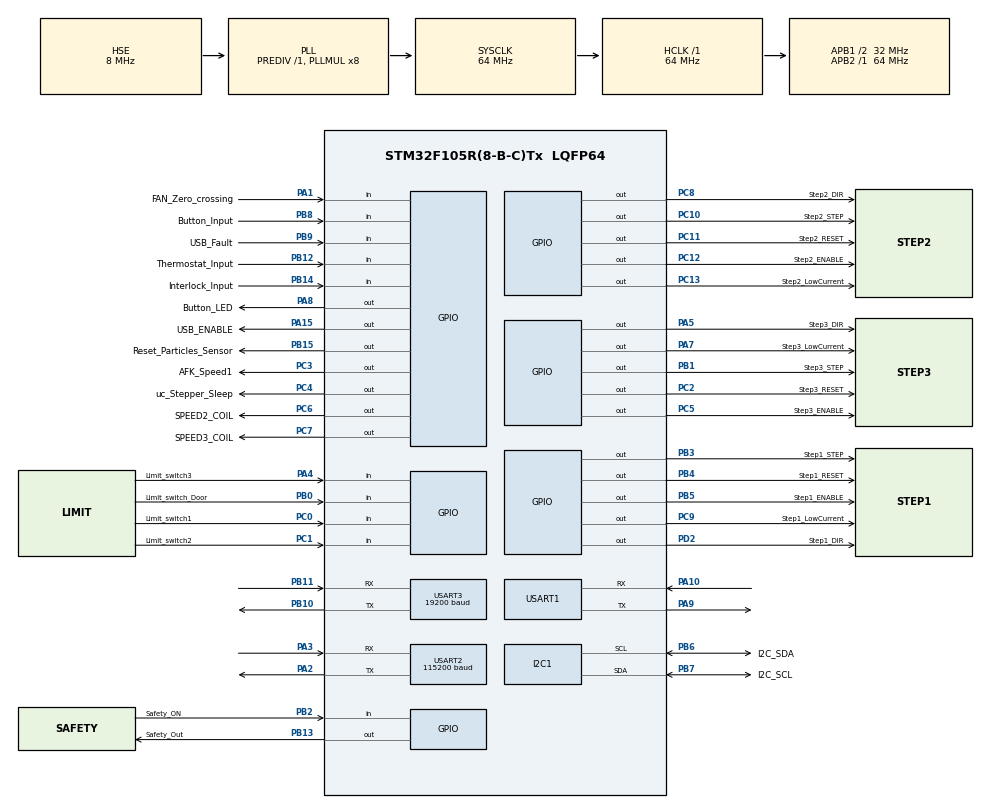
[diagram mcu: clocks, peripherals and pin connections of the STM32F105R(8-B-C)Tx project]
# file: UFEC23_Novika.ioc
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NVIC.I2C1_EV_IRQn=true\:5\:0\:false\:false\:true\:true\:true\:true
PB10.Mode=Asynchronous
RCC.Prediv2=RCC_HSE_PREDIV2_DIV2
PA10.GPIO_PuPd=GPIO_NOPULL
PC12.Signal=GPIO_Output
PB14.GPIO_Label=Interlock_Input
PA3.GPIO_PuPd=GPIO_NOPULL
PC6.GPIO_Label=SPEED2_COIL
VP_RTC_VS_RTC_Activate.Mode=RTC_Enabled
PB6.GPIO_Label=I2C_SDA
PB13.Signal=GPIO_Output
PA5.PinState=GPIO_PIN_SET
PB3.GPIO_Speed=GPIO_SPEED_FREQ_HIGH
RCC.SYSCLKSource=RCC_SYSCLKSOURCE_PLLCLK
USART3.BaudRate=19200
RCC.APB2TimFreq_Value=64000000
PB6.Signal=I2C1_SCL
PC7.Signal=GPIO_Output
PB6.Mode=I2C
PC3.Signal=GPIO_Output
PB2.Signal=GPIO_Input
RCC.PLL2Mul=RCC_PLL2_MUL12
PB12.GPIO_Label=Thermostat_Input
PC4.GPIO_Label=uc_Stepper_Sleep
PB1.GPIO_Speed=GPIO_SPEED_FREQ_HIGH
PB1.GPIO_Label=Step3_STEP
PA8.Signal=GPIO_Output
VP_FREERTOS_VS_CMSIS_V1.Mode=CMSIS_V1
NVIC.I2C1_ER_IRQn=true\:5\:0\:false\:false\:true\:true\:true\:true
Mcu.Package=LQFP64
PB9.Signal=GPIO_Input
PB1.Signal=GPIO_Output
FREERTOS.configUSE_NEWLIB_REENTRANT=0
NVIC.TimeBase=TIM1_UP_IRQn
NVIC.TimeBaseIP=TIM1
PA10.Signal=USART1_RX
VP_RTC_VS_RTC_Calendar.Mode=RTC_Calendar
RCC.APB1TimFreq_Value=64000000
NVIC.USART1_IRQn=true\:5\:0\:false\:false\:true\:true\:true\:true
PA4.GPIO_Label=Limit_switch3
FREERTOS.Tasks01=Algo_task,0,512,Algo_Init,As weak,NULL,Dynamic,NULL,NULL;MotorManager,0,128,Motor_task,As external,NULL,Dynamic,NULL,NULL
PB8.GPIO_PuPd=GPIO_NOPULL
PC2.Signal=GPIO_Output
PC6.Signal=GPIO_Output
PC0.Signal=GPIO_Input
RCC.APB1CLKDivider=RCC_HCLK_DIV2
USART2.BaudRate=115200
PA3.Mode=Asynchronous
PB8.GPIO_Label=Button_Input
PA8.GPIO_Label=Button_LED
PB11.Mode=Asynchronous
PC12.PinState=GPIO_PIN_SET
Dma.USART1_RX.0.Direction=DMA_PERIPH_TO_MEMORY
PA9.Signal=USART1_TX
Dma.USART1_RX.0.PeriphInc=DMA_PINC_DISABLE
PB10.Signal=USART3_TX
PB14.Signal=GPIO_Input
PA5.Signal=GPIO_Output
PC13-TAMPER-RTC.GPIO_Label=Step2_LowCurrent
PB4.GPIO_Label=Step1_RESET
PB15.GPIO_Label=Reset_Particles_Sensor
PA1.GPIO_Label=FAN_Zero_crossing
PA13.Mode=Serial_Wire
PC7.GPIO_Label=SPEED3_COIL
PA4.Signal=GPIO_Input
PB5.Signal=GPIO_Output
PA5.GPIO_Label=Step3_DIR
PC12.GPIO_Label=Step2_ENABLE
USART1.VirtualMode=VM_ASYNC
ProjectManager.HeapSize=0x200
FREERTOS.Timers01=Timer,TimerCallback,osTimerPeriodic,Default,NULL,Dynamic,NULL
NVIC.PriorityGroup=NVIC_PRIORITYGROUP_4
PC3.GPIO_Label=AFK_Speed1
PC3.GPIO_ModeDefaultOutputPP=GPIO_MODE_OUTPUT_PP
PD2.Signal=GPIO_Output
PB0.Signal=GPIO_Input
PC1.Signal=GPIO_Input
PD2.GPIO_Label=Step1_DIR
Mcu.Family=STM32F1
NVIC.USART3_IRQn=true\:5\:0\:false\:false\:true\:true\:true\:true
NVIC.DMA1_Channel5_IRQn=true\:5\:0\:false\:false\:true\:true\:false\:true
PC10.Signal=GPIO_Output
PC0.GPIO_Label=Limit_switch1
PB0.GPIO_Label=Limit_switch_Door
PC10.GPIO_Speed=GPIO_SPEED_FREQ_HIGH
NVIC.TIM1_UP_IRQn=true\:0\:0\:false\:false\:true\:false\:false\:true
PB11.GPIO_PuPd=GPIO_NOPULL
PB13.GPIO_Label=Safety_Out
PB11.Signal=USART3_RX
PB15.Signal=GPIO_Output
PB15.PinState=GPIO_PIN_SET
ProjectManager.StackSize=0x400
PC3.PinState=GPIO_PIN_SET
PD1-OSC_OUT.Signal=RCC_OSC_OUT
VP_RTC_No_RTC_Output.Mode=RTC_OUT_NO
PA15.GPIO_Label=USB_ENABLE
RCC.HCLKFreq_Value=64000000
PB5.PinState=GPIO_PIN_SET
RCC.AHBFreq_Value=64000000
Dma.USART1_RX.0.Priority=DMA_PRIORITY_LOW
FREERTOS.configUSE_TIMERS=1
RCC.PLLMUL=RCC_PLL_MUL8
PA14.Mode=Serial_Wire
VP_SYS_VS_tim1.Mode=TIM1
PC11.GPIO_Label=Step2_RESET
PB7.Signal=I2C1_SDA
SH.S_TIM3_CH1.0=TIM3_CH1
Dma.USART1_RX.0.MemInc=DMA_MINC_ENABLE
FREERTOS.configTOTAL_HEAP_SIZE=8192
PB7.GPIO_Label=I2C_SCL
PA6.Signal=S_TIM3_CH1
USART2.VirtualMode=VM_ASYNC
PA15.Signal=GPIO_Output
PB5.GPIO_Label=Step1_ENABLE
Dma.USART1_RX.0.Mode=DMA_CIRCULAR
PC5.Signal=GPIO_Output
Dma.Request0=USART1_RX
PB4.PinState=GPIO_PIN_SET
PC2.GPIO_Label=Step3_RESET
Dma.USART1_RX.0.Instance=DMA1_Channel5
PA8.PinState=GPIO_PIN_SET
PB4.Signal=GPIO_Output
PA3.Signal=USART2_RX
PB3.GPIO_Label=Step1_STEP
RCC.PLLSourceVirtual=RCC_PLLSOURCE_HSE
PD1-OSC_OUT.Mode=HSE-External-Oscillator
Dma.USART1_RX.0.PeriphDataAlignment=DMA_PDATAALIGN_BYTE
PB9.GPIO_Label=USB_Fault
PC10.GPIO_Label=Step2_STEP
PA10.Mode=Asynchronous
PC9.GPIO_Label=Step1_LowCurrent
PC11.Signal=GPIO_Output
PC8.Signal=GPIO_Output
PC4.Signal=GPIO_Output
PC13-TAMPER-RTC.Signal=GPIO_Output
PD0-OSC_IN.Signal=RCC_OSC_IN
NVIC.USART2_IRQn=true\:5\:0\:false\:false\:true\:true\:true\:true
FREERTOS.INCLUDE_uxTaskGetStackHighWaterMark=1
PC8.GPIO_Label=Step2_DIR
PA13.Signal=SYS_JTMS-SWDIO
PA9.Mode=Asynchronous
ProjectManager.TargetToolchain=STM32CubeIDE
RCC.USBFreq_Value=42666666.666666664
PA1.Signal=GPIO_Input
PD0-OSC_IN.Mode=HSE-External-Oscillator
board=custom
RCC.APB2Freq_Value=64000000
PC11.PinState=GPIO_PIN_SET
PC1.GPIO_Label=Limit_switch2
Dma.USART1_RX.0.MemDataAlignment=DMA_MDATAALIGN_BYTE
Mcu.Name=STM32F105R(8-B-C)Tx
PA2.Signal=USART2_TX
PB3.Signal=GPIO_Output
RCC.SYSCLKFreq_VALUE=64000000
PA7.GPIO_Label=Step3_LowCurrent
PC2.PinState=GPIO_PIN_SET
PC5.PinState=GPIO_PIN_SET
PC5.GPIO_Label=Step3_ENABLE
USART3.VirtualMode=VM_ASYNC
PB7.Mode=I2C
PA14.Signal=SYS_JTCK-SWCLK
PB2.GPIO_Label=Safety_ON
PA2.Mode=Asynchronous
PB8.Signal=GPIO_Input
PC9.Signal=GPIO_Output
RCC.APB1Freq_Value=32000000
PB12.Signal=GPIO_Input
PA7.Signal=GPIO_Output

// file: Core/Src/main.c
/* USER CODE BEGIN Header */
/**
  ******************************************************************************
  * @file           : main.c
  * @brief          : Main program body
  ******************************************************************************
  * @attention
  *
  * <h2><center>&copy; Copyright (c) 2023 STMicroelectronics.
  * All rights reserved.</center></h2>
  *
  * This software component is licensed by ST under Ultimate Liberty license
  * SLA0044, the "License"; You may not use this file except in compliance with
  * the License. You may obtain a copy of the License at:
  *                             www.st.com/SLA0044
  *
  ******************************************************************************
  */
/* USER CODE END Header */
#include "main.h"
#include "cmsis_os.h"

/* USER CODE BEGIN Includes */
#include "Algo.h"
#include "message_buffer.h"
/* USER CODE END Includes */

I2C_HandleTypeDef hi2c1;

RTC_HandleTypeDef hrtc;

UART_HandleTypeDef huart1;
UART_HandleTypeDef huart2;
UART_HandleTypeDef huart3;
DMA_HandleTypeDef hdma_usart1_rx;

osThreadId Algo_taskHandle;
osThreadId MotorManagerHandle;
osTimerId TimerHandle;
/* USER CODE BEGIN PV */
MessageBufferHandle_t MotorControlsHandle;
QueueHandle_t MotorInPlaceHandle;
/* USER CODE END PV */

void SystemClock_Config(void);
static void MX_GPIO_Init(void);
static void MX_DMA_Init(void);
static void MX_RTC_Init(void);
static void MX_USART1_UART_Init(void);
void Algo_Init(void const * argument);
extern void Motor_task(void const * argument);
void TimerCallback(void const * argument);

int main(void)
{

  /* MCU Configuration--------------------------------------------------------*/

  /* Reset of all peripherals, Initializes the Flash interface and the Systick. */
  HAL_Init();

  /* Configure the system clock */
  SystemClock_Config();

  /* Initialize all configured peripherals */
  MX_GPIO_Init();
  MX_DMA_Init();
  MX_I2C1_Init();
  MX_RTC_Init();
  MX_USART1_UART_Init();
  MX_USART3_UART_Init();
  MX_USART2_UART_Init();

  /* Create the timer(s) */
  /* definition and creation of Timer */
  osTimerDef(Timer, TimerCallback);
  TimerHandle = osTimerCreate(osTimer(Timer), osTimerPeriodic, NULL);

  /* USER CODE BEGIN RTOS_QUEUES */
  /* add queues, ... */
	MotorControlsHandle = xMessageBufferCreate(10);
	MotorInPlaceHandle = xQueueCreate(1, sizeof(bool));

  /* USER CODE END RTOS_QUEUES */

  /* Create the thread(s) */
  /* definition and creation of Algo_task */
  osThreadDef(Algo_task, Algo_Init, osPriorityNormal, 0, 512);
  Algo_taskHandle = osThreadCreate(osThread(Algo_task), NULL);

  /* definition and creation of MotorManager */
  osThreadDef(MotorManager, Motor_task, osPriorityAboveNormal, 0, 128);
  MotorManagerHandle = osThreadCreate(osThread(MotorManager), NULL);

  /* Start scheduler */
  osKernelStart();

  /* We should never get here as control is now taken by the scheduler */
  /* Infinite loop */
  while (1)
  {

  }
}

void SystemClock_Config(void)
{
  RCC_OscInitTypeDef RCC_OscInitStruct = {0};
  RCC_ClkInitTypeDef RCC_ClkInitStruct = {0};
  RCC_PeriphCLKInitTypeDef PeriphClkInit = {0};

  /** Initializes the RCC Oscillators according to the specified parameters
  * in the RCC_OscInitTypeDef structure.
  */
  RCC_OscInitStruct.OscillatorType = RCC_OSCILLATORTYPE_LSI|RCC_OSCILLATORTYPE_HSE;
  RCC_OscInitStruct.HSEState = RCC_HSE_ON;
  RCC_OscInitStruct.HSEPredivValue = RCC_HSE_PREDIV_DIV1;
  RCC_OscInitStruct.HSIState = RCC_HSI_ON;
  RCC_OscInitStruct.LSIState = RCC_LSI_ON;
  RCC_OscInitStruct.Prediv1Source = RCC_PREDIV1_SOURCE_HSE;
  RCC_OscInitStruct.PLL.PLLState = RCC_PLL_ON;
  RCC_OscInitStruct.PLL.PLLSource = RCC_PLLSOURCE_HSE;
  RCC_OscInitStruct.PLL.PLLMUL = RCC_PLL_MUL8;
  RCC_OscInitStruct.PLL2.PLL2State = RCC_PLL_NONE;
  if (HAL_RCC_OscConfig(&RCC_OscInitStruct) != HAL_OK)
  {
    Error_Handler();
  }
  /** Initializes the CPU, AHB and APB buses clocks
  */
  RCC_ClkInitStruct.ClockType = RCC_CLOCKTYPE_HCLK|RCC_CLOCKTYPE_SYSCLK
                              |RCC_CLOCKTYPE_PCLK1|RCC_CLOCKTYPE_PCLK2;
  RCC_ClkInitStruct.SYSCLKSource = RCC_SYSCLKSOURCE_PLLCLK;
  RCC_ClkInitStruct.AHBCLKDivider = RCC_SYSCLK_DIV1;
  RCC_ClkInitStruct.APB1CLKDivider = RCC_HCLK_DIV2;
  RCC_ClkInitStruct.APB2CLKDivider = RCC_HCLK_DIV1;

  if (HAL_RCC_ClockConfig(&RCC_ClkInitStruct, FLASH_LATENCY_2) != HAL_OK)
  {
    Error_Handler();
  }
  PeriphClkInit.PeriphClockSelection = RCC_PERIPHCLK_RTC;
  PeriphClkInit.RTCClockSelection = RCC_RTCCLKSOURCE_LSI;
  if (HAL_RCCEx_PeriphCLKConfig(&PeriphClkInit) != HAL_OK)
  {
    Error_Handler();
  }
  /** Configure the Systick interrupt time
  */
  __HAL_RCC_PLLI2S_ENABLE();
}

void MX_I2C1_Init(void)
{

  hi2c1.Instance = I2C1;
  hi2c1.Init.ClockSpeed = 100000;
  hi2c1.Init.DutyCycle = I2C_DUTYCYCLE_2;
  hi2c1.Init.OwnAddress1 = 0;
  hi2c1.Init.AddressingMode = I2C_ADDRESSINGMODE_7BIT;
  hi2c1.Init.DualAddressMode = I2C_DUALADDRESS_DISABLE;
  hi2c1.Init.OwnAddress2 = 0;
  hi2c1.Init.GeneralCallMode = I2C_GENERALCALL_DISABLE;
  hi2c1.Init.NoStretchMode = I2C_NOSTRETCH_DISABLE;
  if (HAL_I2C_Init(&hi2c1) != HAL_OK)
  {
    Error_Handler();
  }

}

static void MX_RTC_Init(void)
{

  RTC_TimeTypeDef sTime = {0};
  RTC_DateTypeDef DateToUpdate = {0};

  /** Initialize RTC Only
  */
  hrtc.Instance = RTC;
  hrtc.Init.AsynchPrediv = RTC_AUTO_1_SECOND;
  hrtc.Init.OutPut = RTC_OUTPUTSOURCE_NONE;
  if (HAL_RTC_Init(&hrtc) != HAL_OK)
  {
    Error_Handler();
  }

  /** Initialize RTC and set the Time and Date
  */
  sTime.Hours = 0x0;
  sTime.Minutes = 0x0;
  sTime.Seconds = 0x0;

  if (HAL_RTC_SetTime(&hrtc, &sTime, RTC_FORMAT_BCD) != HAL_OK)
  {
    Error_Handler();
  }
  DateToUpdate.WeekDay = RTC_WEEKDAY_MONDAY;
  DateToUpdate.Month = RTC_MONTH_JANUARY;
  DateToUpdate.Date = 0x1;
  DateToUpdate.Year = 0x0;

  if (HAL_RTC_SetDate(&hrtc, &DateToUpdate, RTC_FORMAT_BCD) != HAL_OK)
  {
    Error_Handler();
  }

}

static void MX_USART1_UART_Init(void)
{

  huart1.Instance = USART1;
  huart1.Init.BaudRate = 115200;
  huart1.Init.WordLength = UART_WORDLENGTH_8B;
  huart1.Init.StopBits = UART_STOPBITS_1;
  huart1.Init.Parity = UART_PARITY_NONE;
  huart1.Init.Mode = UART_MODE_TX_RX;
  huart1.Init.HwFlowCtl = UART_HWCONTROL_NONE;
  huart1.Init.OverSampling = UART_OVERSAMPLING_16;
  if (HAL_UART_Init(&huart1) != HAL_OK)
  {
    Error_Handler();
  }

}

void MX_USART2_UART_Init(void)
{

  huart2.Instance = USART2;
  huart2.Init.BaudRate = 115200;
  huart2.Init.WordLength = UART_WORDLENGTH_8B;
  huart2.Init.StopBits = UART_STOPBITS_1;
  huart2.Init.Parity = UART_PARITY_NONE;
  huart2.Init.Mode = UART_MODE_TX_RX;
  huart2.Init.HwFlowCtl = UART_HWCONTROL_NONE;
  huart2.Init.OverSampling = UART_OVERSAMPLING_16;
  if (HAL_UART_Init(&huart2) != HAL_OK)
  {
    Error_Handler();
  }

}

void MX_USART3_UART_Init(void)
{

  huart3.Instance = USART3;
  huart3.Init.BaudRate = 19200;
  huart3.Init.WordLength = UART_WORDLENGTH_8B;
  huart3.Init.StopBits = UART_STOPBITS_1;
  huart3.Init.Parity = UART_PARITY_NONE;
  huart3.Init.Mode = UART_MODE_TX_RX;
  huart3.Init.HwFlowCtl = UART_HWCONTROL_NONE;
  huart3.Init.OverSampling = UART_OVERSAMPLING_16;
  if (HAL_UART_Init(&huart3) != HAL_OK)
  {
    Error_Handler();
  }

}

static void MX_DMA_Init(void)
{

  /* DMA controller clock enable */
  __HAL_RCC_DMA1_CLK_ENABLE();

  /* DMA interrupt init */
  /* DMA1_Channel5_IRQn interrupt configuration */
  HAL_NVIC_SetPriority(DMA1_Channel5_IRQn, 5, 0);
  HAL_NVIC_EnableIRQ(DMA1_Channel5_IRQn);

}

static void MX_GPIO_Init(void)
{
  GPIO_InitTypeDef GPIO_InitStruct = {0};

  /* GPIO Ports Clock Enable */
  __HAL_RCC_GPIOC_CLK_ENABLE();
  __HAL_RCC_GPIOD_CLK_ENABLE();
  __HAL_RCC_GPIOA_CLK_ENABLE();
  __HAL_RCC_GPIOB_CLK_ENABLE();

  /*Configure GPIO pin Output Level */
  HAL_GPIO_WritePin(GPIOC, Step2_LowCurrent_Pin|uc_Stepper_Sleep_Pin|SPEED2_COIL_Pin|SPEED3_COIL_Pin
                          |Step2_DIR_Pin|Step1_LowCurrent_Pin|Step2_STEP_Pin, GPIO_PIN_RESET);

  /*Configure GPIO pin Output Level */
  HAL_GPIO_WritePin(GPIOC, Step3_RESET_Pin|AFK_Speed1_Pin|Step3_ENABLE_Pin|Step2_RESET_Pin
                          |Step2_ENABLE_Pin, GPIO_PIN_SET);

  /*Configure GPIO pin Output Level */
  HAL_GPIO_WritePin(GPIOA, Step3_DIR_Pin|Button_LED_Pin, GPIO_PIN_SET);

  /*Configure GPIO pin Output Level */
  HAL_GPIO_WritePin(GPIOA, Step3_LowCurrent_Pin|USB_ENABLE_Pin, GPIO_PIN_RESET);

  /*Configure GPIO pin Output Level */
  HAL_GPIO_WritePin(GPIOB, Step3_STEP_Pin|Safety_Out_Pin|Step1_STEP_Pin, GPIO_PIN_RESET);

  /*Configure GPIO pin Output Level */
  HAL_GPIO_WritePin(GPIOB, Reset_Particles_Sensor_Pin|Step1_RESET_Pin|Step1_ENABLE_Pin, GPIO_PIN_SET);

  /*Configure GPIO pin Output Level */
  HAL_GPIO_WritePin(Step1_DIR_GPIO_Port, Step1_DIR_Pin, GPIO_PIN_RESET);

  /*Configure GPIO pins : Step2_LowCurrent_Pin Step3_RESET_Pin AFK_Speed1_Pin uc_Stepper_Sleep_Pin
                           Step3_ENABLE_Pin SPEED2_COIL_Pin SPEED3_COIL_Pin Step2_DIR_Pin
                           Step1_LowCurrent_Pin Step2_RESET_Pin Step2_ENABLE_Pin */
  GPIO_InitStruct.Pin = Step2_LowCurrent_Pin|Step3_RESET_Pin|AFK_Speed1_Pin|uc_Stepper_Sleep_Pin
                          |Step3_ENABLE_Pin|SPEED2_COIL_Pin|SPEED3_COIL_Pin|Step2_DIR_Pin
                          |Step1_LowCurrent_Pin|Step2_RESET_Pin|Step2_ENABLE_Pin;
  GPIO_InitStruct.Mode = GPIO_MODE_OUTPUT_PP;
  GPIO_InitStruct.Pull = GPIO_NOPULL;
  GPIO_InitStruct.Speed = GPIO_SPEED_FREQ_LOW;
  HAL_GPIO_Init(GPIOC, &GPIO_InitStruct);

  /*Configure GPIO pins : Limit_switch1_Pin Limit_switch2_Pin */
  GPIO_InitStruct.Pin = Limit_switch1_Pin|Limit_switch2_Pin;
  GPIO_InitStruct.Mode = GPIO_MODE_INPUT;
  GPIO_InitStruct.Pull = GPIO_NOPULL;
  HAL_GPIO_Init(GPIOC, &GPIO_InitStruct);

  /*Configure GPIO pins : FAN_Zero_crossing_Pin Limit_switch3_Pin */
  GPIO_InitStruct.Pin = FAN_Zero_crossing_Pin|Limit_switch3_Pin;
  GPIO_InitStruct.Mode = GPIO_MODE_INPUT;
  GPIO_InitStruct.Pull = GPIO_NOPULL;
  HAL_GPIO_Init(GPIOA, &GPIO_InitStruct);

  /*Configure GPIO pins : Step3_DIR_Pin Step3_LowCurrent_Pin Button_LED_Pin USB_ENABLE_Pin */
  GPIO_InitStruct.Pin = Step3_DIR_Pin|Step3_LowCurrent_Pin|Button_LED_Pin|USB_ENABLE_Pin;
  GPIO_InitStruct.Mode = GPIO_MODE_OUTPUT_PP;
  GPIO_InitStruct.Pull = GPIO_NOPULL;
  GPIO_InitStruct.Speed = GPIO_SPEED_FREQ_LOW;
  HAL_GPIO_Init(GPIOA, &GPIO_InitStruct);

  /*Configure GPIO pin : PA6 */
  GPIO_InitStruct.Pin = GPIO_PIN_6;
  GPIO_InitStruct.Mode = GPIO_MODE_AF_PP;
  GPIO_InitStruct.Speed = GPIO_SPEED_FREQ_LOW;
  HAL_GPIO_Init(GPIOA, &GPIO_InitStruct);

  /*Configure GPIO pins : Limit_switch_Door_Pin Safety_ON_Pin Thermostat_Input_Pin Interlock_Input_Pin
                           Button_Input_Pin USB_Fault_Pin */
  GPIO_InitStruct.Pin = Limit_switch_Door_Pin|Safety_ON_Pin|Thermostat_Input_Pin|Interlock_Input_Pin
                          |Button_Input_Pin|USB_Fault_Pin;
  GPIO_InitStruct.Mode = GPIO_MODE_INPUT;
  GPIO_InitStruct.Pull = GPIO_NOPULL;
  HAL_GPIO_Init(GPIOB, &GPIO_InitStruct);

  /*Configure GPIO pins : Step3_STEP_Pin Step1_STEP_Pin */
  GPIO_InitStruct.Pin = Step3_STEP_Pin|Step1_STEP_Pin;
  GPIO_InitStruct.Mode = GPIO_MODE_OUTPUT_PP;
  GPIO_InitStruct.Pull = GPIO_NOPULL;
  GPIO_InitStruct.Speed = GPIO_SPEED_FREQ_HIGH;
  HAL_GPIO_Init(GPIOB, &GPIO_InitStruct);

  /*Configure GPIO pins : Safety_Out_Pin Reset_Particles_Sensor_Pin Step1_RESET_Pin Step1_ENABLE_Pin */
  GPIO_InitStruct.Pin = Safety_Out_Pin|Reset_Particles_Sensor_Pin|Step1_RESET_Pin|Step1_ENABLE_Pin;
  GPIO_InitStruct.Mode = GPIO_MODE_OUTPUT_PP;
  GPIO_InitStruct.Pull = GPIO_NOPULL;
  GPIO_InitStruct.Speed = GPIO_SPEED_FREQ_LOW;
  HAL_GPIO_Init(GPIOB, &GPIO_InitStruct);

  /*Configure GPIO pin : Step2_STEP_Pin */
  GPIO_InitStruct.Pin = Step2_STEP_Pin;
  GPIO_InitStruct.Mode = GPIO_MODE_OUTPUT_PP;
  GPIO_InitStruct.Pull = GPIO_NOPULL;
  GPIO_InitStruct.Speed = GPIO_SPEED_FREQ_HIGH;
  HAL_GPIO_Init(Step2_STEP_GPIO_Port, &GPIO_InitStruct);

  /*Configure GPIO pin : Step1_DIR_Pin */
  GPIO_InitStruct.Pin = Step1_DIR_Pin;
  GPIO_InitStruct.Mode = GPIO_MODE_OUTPUT_PP;
  GPIO_InitStruct.Pull = GPIO_NOPULL;
  GPIO_InitStruct.Speed = GPIO_SPEED_FREQ_LOW;
  HAL_GPIO_Init(Step1_DIR_GPIO_Port, &GPIO_InitStruct);

}

__weak void Algo_Init(void const * argument)
{
  for(;;)
  {
    osDelay(1);
  }
}

/* TimerCallback function */
void TimerCallback(void const * argument)
{
}

 /**
  * @brief  Period elapsed callback in non blocking mode
  * @note   This function is called  when TIM1 interrupt took place, inside
  * HAL_TIM_IRQHandler(). It makes a direct call to HAL_IncTick() to increment
  * a global variable "uwTick" used as application time base.
  * @param  htim : TIM handle
  * @retval None
  */
void HAL_TIM_PeriodElapsedCallback(TIM_HandleTypeDef *htim)
{
  if (htim->Instance == TIM1) {
    HAL_IncTick();
  }
}

void Error_Handler(void)
{
  __disable_irq();
  while (1)
  {
  }
}

/************************ (C) COPYRIGHT STMicroelectronics *****END OF FILE****/
